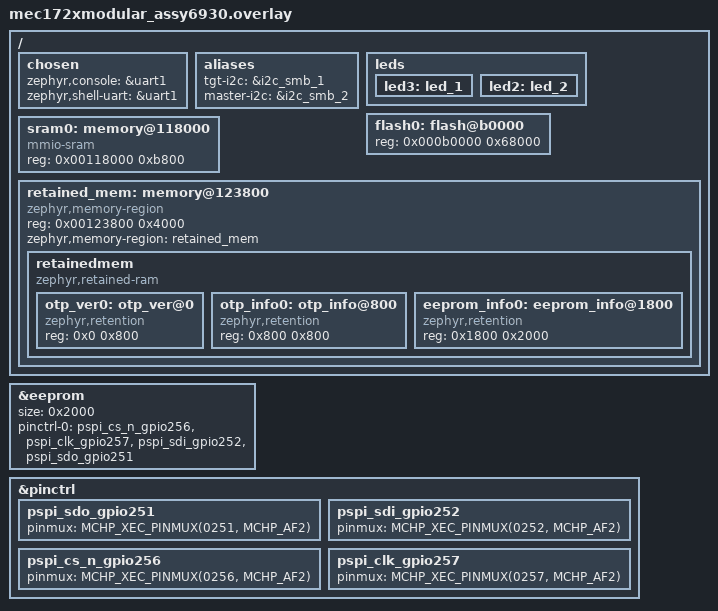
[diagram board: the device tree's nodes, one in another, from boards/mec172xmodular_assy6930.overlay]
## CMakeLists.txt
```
# SPDX-License-Identifier: Apache-2.0

cmake_minimum_required(VERSION 3.20.0)

find_package(Zephyr REQUIRED HINTS $ENV{ZEPHYR_BASE})
project(ram_retention)

target_sources(app PRIVATE src/main.c)
target_sources(app PRIVATE src/otp_backup.c)
```

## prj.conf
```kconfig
# Driver
CONFIG_EEPROM=y

# console
CONFIG_CONSOLE=y
CONFIG_UART_CONSOLE=y
CONFIG_LOG=y

#SHELL
CONFIG_SHELL=y
CONFIG_GPIO_SHELL=y
CONFIG_EEPROM_SHELL=y
CONFIG_SHELL_PROMPT_UART="MCHP:~$ "

# RETENTION
CONFIG_RETAINED_MEM=y
CONFIG_RETENTION=y

CONFIG_REBOOT=y
```

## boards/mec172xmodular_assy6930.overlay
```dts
/*
 * Copyright (c) 2020 Intel Corporation
 *
 * SPDX-License-Identifier: Apache-2.0
 */


/ {
	chosen {
		zephyr,console = &uart1;
		zephyr,shell-uart = &uart1;
	};

	aliases {
        tgt-i2c = &i2c_smb_1;
        master-i2c = &i2c_smb_2;
    };

	leds {
		led3: led_1 {
			status = "okay";
		};
		led2: led_2 {
			status = "okay";
		};
	};

	/delete-node/ flash@c0000;
	/delete-node/ memory@118000;
	flash0: flash@b0000 {
		reg = <0x000b0000 0x68000>;
	};

	sram0: memory@118000 {
		compatible = "mmio-sram";
		// reg = <0x00118000 0xf800>;
		reg = <0x00118000 0xb800>;
	};

	retained_mem: memory@123800 {
		compatible = "zephyr,memory-region", "mmio-sram";
		reg = <0x00123800 0x4000>;
		zephyr,memory-region = "retained_mem";
		status = "okay";

		retainedmem {
			compatible = "zephyr,retained-ram";
			status = "okay";
			#address-cells = <1>;
			#size-cells = <1>;

			otp_ver0: otp_ver@0 {
				compatible = "zephyr,retention";
				status = "okay";
				reg = < 0x0 0x800 >;
			};

			otp_info0: otp_info@800 {
				compatible = "zephyr,retention";
				status = "okay";
				reg = < 0x800 0x800 >;
			};

			eeprom_info0: eeprom_info@1800 {
				compatible = "zephyr,retention";
				status = "okay";
				reg = < 0x1800 0x2000 >;
			};
		};
	};
};

&eeprom {
	size = < 0x2000 >;
	pinctrl-0 = <&pspi_cs_n_gpio256
		     &pspi_clk_gpio257
		     &pspi_sdi_gpio252
		     &pspi_sdo_gpio251>;
	pinctrl-names = "default";
	status = "okay";
};

&pinctrl {
	/omit-if-no-ref/ pspi_sdo_gpio251: pspi_sdo_gpio251 {
		pinmux = <MCHP_XEC_PINMUX(0251, MCHP_AF2)>;
	};
	/omit-if-no-ref/ pspi_sdi_gpio252: pspi_sdi_gpio252 {
		pinmux = <MCHP_XEC_PINMUX(0252, MCHP_AF2)>;
	};
	/omit-if-no-ref/ pspi_cs_n_gpio256: pspi_cs_n_gpio256 {
		pinmux = <MCHP_XEC_PINMUX(0256, MCHP_AF2)>;
	};
	/omit-if-no-ref/ pspi_clk_gpio257: pspi_clk_gpio257 {
		pinmux = <MCHP_XEC_PINMUX(0257, MCHP_AF2)>;
	};
};


// &uart0 {
// 	status = "okay";
// 	current-speed = < 0x1c200 >;
// 	pinctrl-0 = < &uart0_tx_gpio104 &uart0_rx_gpio105 >;
// 	pinctrl-names = "default";
// };
```

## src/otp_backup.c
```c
#include <zephyr/device.h>
#include <zephyr/devicetree.h>
#include <zephyr/drivers/eeprom.h>
#include <zephyr/drivers/retained_mem.h>
#include <zephyr/kernel.h>
#include <zephyr/logging/log.h>
#include <zephyr/retention/retention.h>

LOG_MODULE_REGISTER(app_retained, LOG_LEVEL_INF);

#include <stdlib.h>

#define OTP_WRITE_SHELL_SUCCESS (0x00)
#define OTP_WRITE_SHELL_SUCCESS_ALREADY_SAME (0xFF)

#define api_efuse_byte_write ((api_efuse_byte_write_td)0x0000f00d)
#define api_efuse_byte_read ((api_efuse_byte_read_td)0x0000f009)
#define api_rom_ver ((api_rom_ver_td)0x0000f001)

typedef uint8_t (*api_efuse_byte_write_td)(uint16_t byte_idx, uint8_t in_data);
typedef uint8_t (*api_efuse_byte_read_td)(uint16_t byte_idx, uint8_t *out_data);
typedef uint32_t (*api_rom_ver_td)(void);

/* 1. 從 Devicetree 取得我們定義的 boot_info0 裝置實例 */
static const struct device *otp_ver = DEVICE_DT_GET(DT_NODELABEL(otp_ver0));
static const struct device *otp_data = DEVICE_DT_GET(DT_NODELABEL(otp_info0));
static const struct device *eeprom_data = DEVICE_DT_GET(DT_NODELABEL(eeprom_info0));

static const struct device *eeprom = DEVICE_DT_GET(DT_NODELABEL(eeprom));

static uint8_t buf[DT_REG_SIZE(DT_NODELABEL(eeprom_info0))] = {0};
static uint32_t rom_ver = 0;

#include <zephyr/init.h>

static int init_config(void) {
    int ret;

    LOG_INF("--- Zephyr Retention system test ---");

    // Check if the retention memory devices are ready
    if (!device_is_ready(otp_ver)) {
        LOG_ERR("OTP version device is not ready!");
        return -1;
    }

    // Read the boot rom version from the ROM API and store it in retention memory
    rom_ver = api_rom_ver();
    LOG_INF("ROM Version: 0x%08X", rom_ver);
    ret = retention_write(otp_ver, 0, (uint8_t *)&rom_ver, sizeof(rom_ver));
    if (ret < 0) {
        LOG_ERR("Failed to write Retention: %d", ret);
        return ret;
    }

    // Check if the retention memory devices are ready
    if (!device_is_ready(otp_data)) {
        LOG_ERR("OTP buffer device is not ready!");
        return -1;
    }

    // Read the OTP data from efuse and store it in retention memory
    for (int i = 0; i < DT_REG_SIZE(DT_NODELABEL(otp_info0)); i++) {
        api_efuse_byte_read(i, &buf[i]);
    }
    ret =
        retention_write(otp_data, 0, buf, DT_REG_SIZE(DT_NODELABEL(otp_info0)));
    if (ret < 0) {
        LOG_ERR("Failed to write Retention: %d", ret);
        return ret;
    }

    memset(buf, 0xAA, sizeof(buf));

    // Check if the retention memory devices are ready
    if (!device_is_ready(eeprom_data)) {
        LOG_ERR("EEPROM buffer device is not ready!");
        return -1;
    }
    if (!device_is_ready(eeprom)) {
        LOG_ERR("EEPROM buffer device is not ready!");
        return -1;
    }

    // Read the EEPROM data and store it in retention memory
    ret = eeprom_read(eeprom, 0, buf, DT_REG_SIZE(DT_NODELABEL(eeprom_info0)));
    if (ret < 0) {
        LOG_ERR("Failed to read EEPROM: %d", ret);
    }
    ret = retention_write(eeprom_data, 0, buf,
                          DT_REG_SIZE(DT_NODELABEL(eeprom_info0)));
    if (ret < 0) {
        LOG_ERR("Failed to write Retention: %d", ret);
        return ret;
    }

    return 0;
}

SYS_INIT(init_config, APPLICATION, 0);
```
